# sam67_dmpac_wrap0_DMPAC_TOP_CFG_SLV_DRU_UTC_DMPAC0_DRU_MMR_CFG_DRU_DRU_SET register map
Vendor: Texas Instruments
Peripheral module from a debugger description file (folder J722S).
Registers are 64-bit, write-only, reset 0x0 unless marked. A register's access mark holds for its fields unless they carry their own. Offsets are as the file gives them; lines under a group give offsets from that group; [hi:lo] are bit positions; {n}, {i} and the like mark numbered series; 'fields as' and 'values as' point back to an identical list; <NAME> marks a mode.

## sam67_dmpac_wrap0_DMPAC_TOP_CFG_SLV_DRU_UTC_DMPAC0_DRU_MMR_CFG_DRU_DRU_SET
0x00 DMPAC_TOP__CFG_SLV__DRU_UTC_DMPAC0__DRU_MMR_CFG__DRU_DRU_DRU_SET_dru_shared_evt_set — DRU Shared Event Set Register
  [0] PROT_ERR — Set the Prot Error event
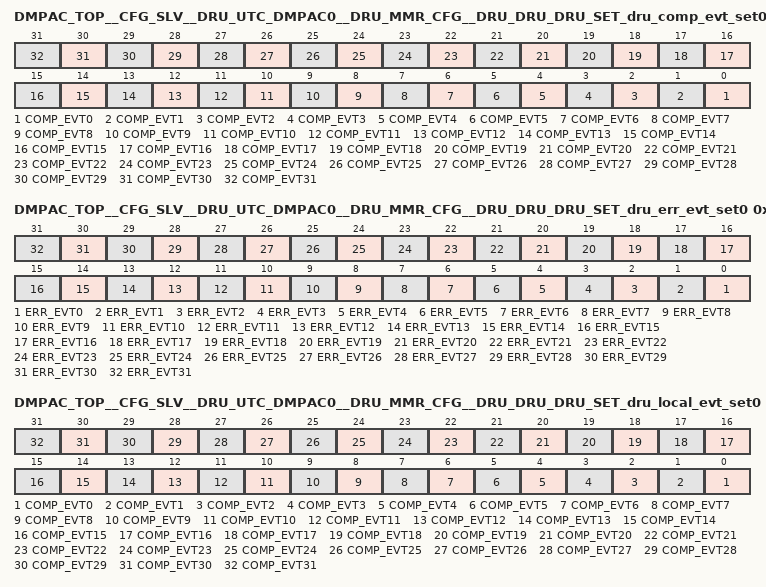
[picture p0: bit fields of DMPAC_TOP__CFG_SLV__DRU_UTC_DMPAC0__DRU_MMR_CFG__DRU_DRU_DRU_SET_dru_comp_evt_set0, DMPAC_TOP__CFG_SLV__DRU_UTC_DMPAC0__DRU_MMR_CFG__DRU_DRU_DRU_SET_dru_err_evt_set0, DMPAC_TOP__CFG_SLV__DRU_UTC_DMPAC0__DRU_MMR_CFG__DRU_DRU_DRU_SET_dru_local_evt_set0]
0x40 DMPAC_TOP__CFG_SLV__DRU_UTC_DMPAC0__DRU_MMR_CFG__DRU_DRU_DRU_SET_dru_comp_evt_set0 — DRU Completion Event Set Register
  [n] COMP_EVT{n} (n=0..31) — Set the Completion Event for channel {n}
0x80 DMPAC_TOP__CFG_SLV__DRU_UTC_DMPAC0__DRU_MMR_CFG__DRU_DRU_DRU_SET_dru_err_evt_set0 — DRU Error Event Set Register
  [n] ERR_EVT{n} (n=0..31) — Set the Error Event for channel {n}
0xC0 DMPAC_TOP__CFG_SLV__DRU_UTC_DMPAC0__DRU_MMR_CFG__DRU_DRU_DRU_SET_dru_local_evt_set0 — DRU Local Event Set Register
  [n] COMP_EVT{n} (n=0..31) — Set the Local Event for channel {n}
